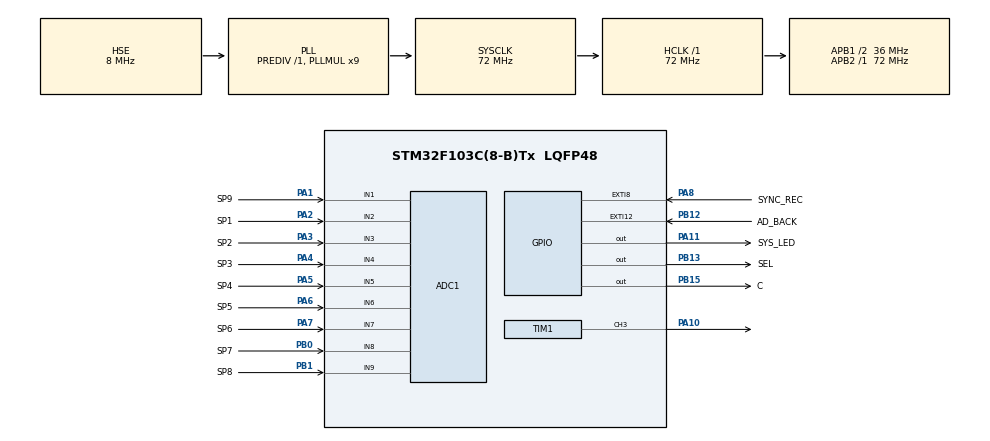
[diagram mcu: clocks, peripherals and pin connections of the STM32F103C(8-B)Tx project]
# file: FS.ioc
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ADC1.Channel-0\#ChannelRegularConversion=ADC_CHANNEL_2
ADC1.Channel-1\#ChannelRegularConversion=ADC_CHANNEL_3
ADC1.Channel-2\#ChannelRegularConversion=ADC_CHANNEL_4
ADC1.Channel-3\#ChannelRegularConversion=ADC_CHANNEL_5
ADC1.Channel-4\#ChannelRegularConversion=ADC_CHANNEL_6
ADC1.Channel-5\#ChannelRegularConversion=ADC_CHANNEL_7
ADC1.Channel-6\#ChannelRegularConversion=ADC_CHANNEL_8
ADC1.Channel-7\#ChannelRegularConversion=ADC_CHANNEL_9
ADC1.Channel-8\#ChannelRegularConversion=ADC_CHANNEL_1
ADC1.ContinuousConvMode=ENABLE
ADC1.NbrOfConversion=9
ADC1.NbrOfConversionFlag=1
ADC1.Rank-0\#ChannelRegularConversion=1
ADC1.Rank-1\#ChannelRegularConversion=2
ADC1.Rank-2\#ChannelRegularConversion=3
ADC1.Rank-3\#ChannelRegularConversion=4
ADC1.Rank-4\#ChannelRegularConversion=5
ADC1.Rank-5\#ChannelRegularConversion=6
ADC1.Rank-6\#ChannelRegularConversion=7
ADC1.Rank-7\#ChannelRegularConversion=8
ADC1.Rank-8\#ChannelRegularConversion=9
ADC1.SamplingTime-0\#ChannelRegularConversion=ADC_SAMPLETIME_1CYCLE_5
ADC1.SamplingTime-1\#ChannelRegularConversion=ADC_SAMPLETIME_1CYCLE_5
ADC1.SamplingTime-2\#ChannelRegularConversion=ADC_SAMPLETIME_1CYCLE_5
ADC1.SamplingTime-3\#ChannelRegularConversion=ADC_SAMPLETIME_1CYCLE_5
ADC1.SamplingTime-4\#ChannelRegularConversion=ADC_SAMPLETIME_1CYCLE_5
ADC1.SamplingTime-5\#ChannelRegularConversion=ADC_SAMPLETIME_1CYCLE_5
ADC1.SamplingTime-6\#ChannelRegularConversion=ADC_SAMPLETIME_1CYCLE_5
ADC1.SamplingTime-7\#ChannelRegularConversion=ADC_SAMPLETIME_1CYCLE_5
ADC1.SamplingTime-8\#ChannelRegularConversion=ADC_SAMPLETIME_1CYCLE_5
ADC1.master=1
Mcu.Family=STM32F1
Mcu.Name=STM32F103C(8-B)Tx
Mcu.Package=LQFP48
NVIC.ADC1_2_IRQn=true\:0\:0\:false\:false\:true\:true\:true\:true
NVIC.EXTI15_10_IRQn=true\:0\:0\:false\:false\:true\:true\:true\:true
NVIC.EXTI9_5_IRQn=true\:0\:0\:false\:false\:true\:true\:true\:true
NVIC.PriorityGroup=NVIC_PRIORITYGROUP_4
PA1.GPIO_Label=SP9
PA1.Signal=ADCx_IN1
PA10.Signal=S_TIM1_CH3
PA11.GPIO_Label=SYS_LED
PA11.GPIO_PuPd=GPIO_NOPULL
PA11.GPIO_Speed=GPIO_SPEED_FREQ_HIGH
PA11.PinState=GPIO_PIN_SET
PA11.Signal=GPIO_Output
PA13.Mode=Serial_Wire
PA13.Signal=SYS_JTMS-SWDIO
PA14.Mode=Serial_Wire
PA14.Signal=SYS_JTCK-SWCLK
PA2.GPIO_Label=SP1
PA2.Signal=ADCx_IN2
PA3.GPIO_Label=SP2
PA3.Signal=ADCx_IN3
PA4.GPIO_Label=SP3
PA4.Signal=ADCx_IN4
PA5.GPIO_Label=SP4
PA5.Signal=ADCx_IN5
PA6.GPIO_Label=SP5
PA6.Signal=ADCx_IN6
PA7.GPIO_Label=SP6
PA7.Signal=ADCx_IN7
PA8.GPIO_Label=SYNC_REC
PA8.GPIO_ModeDefaultEXTI=GPIO_MODE_IT_RISING_FALLING
PA8.GPIO_PuPd=GPIO_PULLDOWN
PA8.Signal=GPXTI8
PB0.GPIO_Label=SP7
PB0.Signal=ADCx_IN8
PB1.GPIO_Label=SP8
PB1.Signal=ADCx_IN9
PB12.GPIO_Label=AD_BACK
PB12.GPIO_ModeDefaultEXTI=GPIO_MODE_IT_RISING_FALLING
PB12.GPIO_PuPd=GPIO_PULLDOWN
PB12.Signal=GPXTI12
PB13.GPIO_Label=SEL
PB13.GPIO_Speed=GPIO_SPEED_FREQ_HIGH
PB13.Signal=GPIO_Output
PB15.GPIO_Label=C
PB15.GPIO_PuPd=GPIO_PULLDOWN
PB15.GPIO_Speed=GPIO_SPEED_FREQ_HIGH
PB15.Signal=GPIO_Output
PD0-OSC_IN.Mode=HSE-External-Oscillator
PD0-OSC_IN.Signal=RCC_OSC_IN
PD1-OSC_OUT.Mode=HSE-External-Oscillator
PD1-OSC_OUT.Signal=RCC_OSC_OUT
ProjectManager.HeapSize=0x200
ProjectManager.StackSize=0x400
ProjectManager.TargetToolchain=MDK-ARM V5.32
RCC.ADCPresc=RCC_ADCPCLK2_DIV6
RCC.AHBFreq_Value=72000000
RCC.APB1CLKDivider=RCC_HCLK_DIV2
RCC.APB1Freq_Value=36000000
RCC.APB1TimFreq_Value=72000000
RCC.APB2Freq_Value=72000000
RCC.APB2TimFreq_Value=72000000
RCC.HCLKFreq_Value=72000000
RCC.PLLMUL=RCC_PLL_MUL9
RCC.PLLSourceVirtual=RCC_PLLSOURCE_HSE
RCC.SYSCLKFreq_VALUE=72000000
RCC.SYSCLKSource=RCC_SYSCLKSOURCE_PLLCLK
RCC.USBFreq_Value=72000000
SH.ADCx_IN1.0=ADC1_IN1,IN1
SH.ADCx_IN2.0=ADC1_IN2,IN2
SH.ADCx_IN3.0=ADC1_IN3,IN3
SH.ADCx_IN4.0=ADC1_IN4,IN4
SH.ADCx_IN5.0=ADC1_IN5,IN5
SH.ADCx_IN6.0=ADC1_IN6,IN6
SH.ADCx_IN7.0=ADC1_IN7,IN7
SH.ADCx_IN8.0=ADC1_IN8,IN8
SH.ADCx_IN9.0=ADC1_IN9,IN9
SH.S_TIM1_CH3.0=TIM1_CH3,PWM Generation3 CH3
TIM1.AutoReloadPreload=TIM_AUTORELOAD_PRELOAD_ENABLE
TIM1.Channel-PWM\ Generation3\ CH3=TIM_CHANNEL_3
TIM1.Period=5-1
TIM1.Prescaler=72-1
TIM1.Pulse-PWM\ Generation3\ CH3=2
VP_TIM1_VS_ClockSourceINT.Mode=Internal
board=custom

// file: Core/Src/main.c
/* USER CODE BEGIN Header */
/**
 ******************************************************************************
 * @file           : main.c
 * @brief          : Main program body
 ******************************************************************************
 * @attention
 *
 * Copyright (c) 2024 STMicroelectronics.
 * All rights reserved.
 *
 * This software is licensed under terms that can be found in the LICENSE file
 * in the root directory of this software component.
 * If no LICENSE file comes with this software, it is provided AS-IS.
 *
 ******************************************************************************
 */
/* USER CODE END Header */
#include "main.h"
#include "adc.h"
#include "tim.h"
#include "gpio.h"

void SystemClock_Config(void);

int main(void)
{

  /* USER CODE BEGIN 1 */
  extern volatile uint16_t adc_value[10];

  /* USER CODE END 1 */

  /* MCU Configuration--------------------------------------------------------*/

  /* Reset of all peripherals, Initializes the Flash interface and the Systick. */
  HAL_Init();

  /* Configure the system clock */
  SystemClock_Config();

  /* USER CODE BEGIN SysInit */
  HAL_Delay_us_init(72);
  /* USER CODE END SysInit */

  /* Initialize all configured peripherals */
  MX_GPIO_Init();
  MX_ADC1_Init();
  MX_TIM1_Init();
  /* USER CODE BEGIN 2 */

  // HAL_TIM_PWM_Start(&htim1, TIM_CHANNEL_3);
  HAL_ADCEx_Calibration_Start(&hadc1);
  HAL_ADC_Start(&hadc1);
  /* USER CODE END 2 */

  /* Infinite loop */
  /* USER CODE BEGIN WHILE */
  while (1)
  {
    Read_ADC_Values();

  }

    /* USER CODE END WHILE */

}

void SystemClock_Config(void)
{
  RCC_OscInitTypeDef RCC_OscInitStruct = {0};
  RCC_ClkInitTypeDef RCC_ClkInitStruct = {0};
  RCC_PeriphCLKInitTypeDef PeriphClkInit = {0};

  /** Initializes the RCC Oscillators according to the specified parameters
  * in the RCC_OscInitTypeDef structure.
  */
  RCC_OscInitStruct.OscillatorType = RCC_OSCILLATORTYPE_HSE;
  RCC_OscInitStruct.HSEState = RCC_HSE_ON;
  RCC_OscInitStruct.HSEPredivValue = RCC_HSE_PREDIV_DIV1;
  RCC_OscInitStruct.HSIState = RCC_HSI_ON;
  RCC_OscInitStruct.PLL.PLLState = RCC_PLL_ON;
  RCC_OscInitStruct.PLL.PLLSource = RCC_PLLSOURCE_HSE;
  RCC_OscInitStruct.PLL.PLLMUL = RCC_PLL_MUL9;
  if (HAL_RCC_OscConfig(&RCC_OscInitStruct) != HAL_OK)
  {
    Error_Handler();
  }

  /** Initializes the CPU, AHB and APB buses clocks
  */
  RCC_ClkInitStruct.ClockType = RCC_CLOCKTYPE_HCLK|RCC_CLOCKTYPE_SYSCLK
                              |RCC_CLOCKTYPE_PCLK1|RCC_CLOCKTYPE_PCLK2;
  RCC_ClkInitStruct.SYSCLKSource = RCC_SYSCLKSOURCE_PLLCLK;
  RCC_ClkInitStruct.AHBCLKDivider = RCC_SYSCLK_DIV1;
  RCC_ClkInitStruct.APB1CLKDivider = RCC_HCLK_DIV2;
  RCC_ClkInitStruct.APB2CLKDivider = RCC_HCLK_DIV1;

  if (HAL_RCC_ClockConfig(&RCC_ClkInitStruct, FLASH_LATENCY_2) != HAL_OK)
  {
    Error_Handler();
  }
  PeriphClkInit.PeriphClockSelection = RCC_PERIPHCLK_ADC;
  PeriphClkInit.AdcClockSelection = RCC_ADCPCLK2_DIV6;
  if (HAL_RCCEx_PeriphCLKConfig(&PeriphClkInit) != HAL_OK)
  {
    Error_Handler();
  }
}

void Error_Handler(void)
{
  __disable_irq();
  while (1)
  {
  }
}
